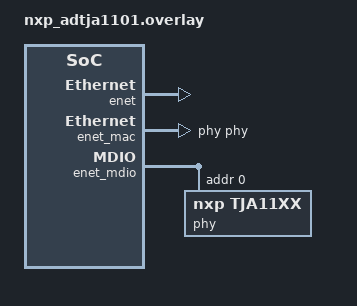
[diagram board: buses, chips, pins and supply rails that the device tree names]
/*
 * Copyright 2024 NXP
 *
 * SPDX-License-Identifier: Apache-2.0
 */

&enet {
	status = "okay";
};

&enet_mac {
	status = "okay";
	phy-handle = <&phy>;
};

&enet_mdio {
	status = "okay";

	phy: phy@0 {
		compatible = "nxp,tja11xx";
		reg = <0>;
		status = "okay";
	};
};

&enet_ptp_clock {
	status = "okay";
};
